# nrf9220_application register map
Vendor: Nordic Semiconductor; Series: nRF92; File version: 1
CPU: CM33 r1p0, little endian, MPU, FPU, 3 interrupt priority bits, 480 interrupts, 4 SAU regions
Registers are 32-bit, read-write, reset 0x0 unless marked. A register's access mark holds for its fields unless they carry their own. Offsets are from the block's base; [hi:lo] are bit positions; lines under a group give offsets from that group; {n}, {i} and the like mark numbered series.

## ICACHEDATA_S — CACHEDATA
Base 0x02F00000
{0x0+0x40*i} SET[{i}] (i=0..1023) group — Unspecified
  {0x0+0x20*j} WAY[{j}] (j=0..1) group — Unspecified
    {0x0+8k} DU[{k}] (k=0..3) group — Unspecified
      {0x0+4l} DATA[{l}] (l=0..1) — Description collection: Cache data bits for DATA[q] in DU[p] (DataUnit) of SET[n], WAY[o].
        [31:0] Data ro

## ICACHEINFO_S — CACHEINFO
Base 0x02F10000
{0x0+8i} SET[{i}] (i=0..1023) group — Unspecified
  {0x0+4j} WAY[{j}] (j=0..1) group — Unspecified
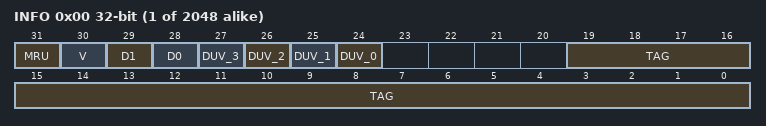
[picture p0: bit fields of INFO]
    0x00 INFO — Description cluster: Cache information for SET[n], WAY[o].
      [31] MRU ro — Most recently used way.
        0=Way0 was most recently used; 1=Way1 was most recently used
      [30] V ro — Line valid bit.
        0=Invalid cache line; 1=Valid cache line
      [29] D1 ro — Dirty status of combined data unit 2 and 3.
        0=Clean data unit; 1=Dirty data unit
      [28] D0 ro — Dirty status of combined data unit 0 and 1.
        0=Clean data unit; 1=Dirty data unit
      [n+24] DUV_{n} ro (n=0..3) — Data unit valid info.
        0=Invalid data unit; 1=Valid data unit
      [19:0] TAG ro — Cache tag.

## GLOBAL_MICR_NS — MICR
Base 0x0FFF6000
0x80 SIPINFO group — SIP-specific device info.
  {0x0+4j} PARTNO[{j}] (j=0..1) ro reset 0xFFFFFFFF — Description collection: SIP part number, encoded in ASCII.
    [31:0] PARTNO — Bits [(n+1)*31-1:n*32] of the SIP part number
  {0x8+j} VARIANT[{j}] (j=0..3) 8-bit ro reset 0xFF — Description collection: SIP VARIANT, encoded in ASCII, ex SIAA, SIBA or SICA.
    [7:0] VARIANT
  {0x2F0+4j} SERIALNO[{j}] (j=0..8) ro reset 0xFFFFFFFF — Description collection: SIP module serial number.
    [31:0] SERIALNO

## GLOBAL_FICR_NS — Factory Information Configuration Registers
Base 0x0FFFE000
0x40 NFC group — Unspecified
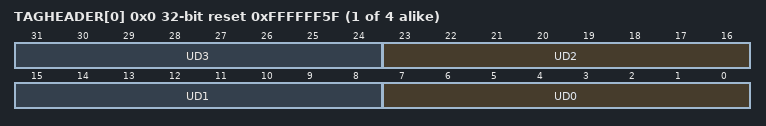
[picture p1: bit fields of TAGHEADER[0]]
  {0x0+4j} TAGHEADER[{j}] (j=0..3) ro reset 0xFFFFFF5F — Description collection: Default header for NFC Tag.
    [8n+7:8n] UD{n} (n=0..3) — Unique identifier byte {n}
0x50 INFO group — Device info
  0x00 CONFIGID ro reset 0xFFFFFFFF — Configuration identifier
    [15:0] HWID — Identification number for the HW
  0x04 PART ro reset 0xFFFFFFFF — Part code
    [31:0] PART
      0xFFFFFFFF=Unspecified
  0x08 VARIANT ro reset 0xFFFFFFFF — Part Variant, Hardware version and Production configuration
    [31:0] VARIANT — Part Variant, Hardware version and Production configuration, encoded as ASCII
      0xFFFFFFFF=Unspecified
  0x0C PACKAGE ro reset 0xFFFFFFFF — Package option
    [31:0] PACKAGE
      0xFFFFFFFF=Unspecified
  0x10 RAM ro reset 0xFFFFFFFF — RAM variant
    [31:0] RAM
      0xFFFFFFFF=Unspecified
  0x14 MRAM ro reset 0xFFFFFFFF — MRAM variant
    [31:0] MRAM
      0xFFFFFFFF=Unspecified
  0x18 CODEPAGESIZE ro reset 0x1000 — Code memory page size in bytes
    [31:0] CODEPAGESIZE
      0xFFFFFFFF=Unspecified
  0x1C CODESIZE ro reset 0x100 — Code memory size
    [31:0] CODESIZE — Code memory size in number of pages
      0xFFFFFFFF=Unspecified
  0x20 DEVICETYPE ro
    [31:0] DEVICETYPE
      0=Die (Device is an physical DIE); 0xFFFFFFFF=FPGA (Device is an FPGA)
0x100 TRIM group — Unspecified
  0x2CC GLOBAL group — Unspecified
    0x00 SAADC group — Unspecified
      {0x0+4l} CAL[{l}] (l=0..2) ro reset 0xFFFFFFFF — Description collection: Trim value for GLOBAL.SAADC.CAL
        [31:0] VALUE — Trim value
      0x0C CALREF ro reset 0xFFFFFFFF — Trim value for GLOBAL.SAADC.CALREF
        [31:0] VALUE — Trim value
      {0x10+4l} LINCALCOEFF[{l}] (l=0..5) ro reset 0xFFFFFFFF — Description collection: Trim value for GLOBAL.SAADC.TRIM.LINCALCOEFF
        [31:0] VALUE — Trim value
    0x2C NFCT group — Unspecified
      0x00 BIASCFG ro reset 0xFFFFFFFF — Trim value for NFCT.BIASCFG
        [31:0] VALUE — Trim value
  0x30C APPLICATION group — Unspecified
    0x00 HSFLL group — Unspecified
      0x00 TRIM group — Unspecified
        0x00 VSUP ro reset 0xFFFFFFFF — Trim value for APPLICATION.HSFLL.TRIM.VSUP
          [31:0] VALUE — Trim value
        {0x4+4m} COARSE[{m}] (m=0..5) ro reset 0xFFFFFFFF — Description collection: Trim value for APPLICATION.HSFLL.TRIM.COARSE
          [31:0] VALUE — Trim value
        {0x1C+4m} FINE[{m}] (m=0..5) ro reset 0xFFFFFFFF — Description collection: Trim value for APPLICATION.HSFLL.TRIM.FINE
          [31:0] VALUE — Trim value
        0x34 TCOEF ro reset 0xFFFFFFFF — Trim value for APPLICATION.HSFLL.TRIM.TCOEF
          [31:0] VALUE — Trim value
    0x38 MEMCONF group — Unspecified
      {0x0+4l} BLOCKTYPE[{l}] (l=0..3) group — Unspecified
        0x00 TRIM ro reset 0xFFFFFFFF — Description cluster: Trim value for APPLICATION.MEMCONF.BLOCKTYPE[n].TRIM
          [31:0] VALUE — Trim value
